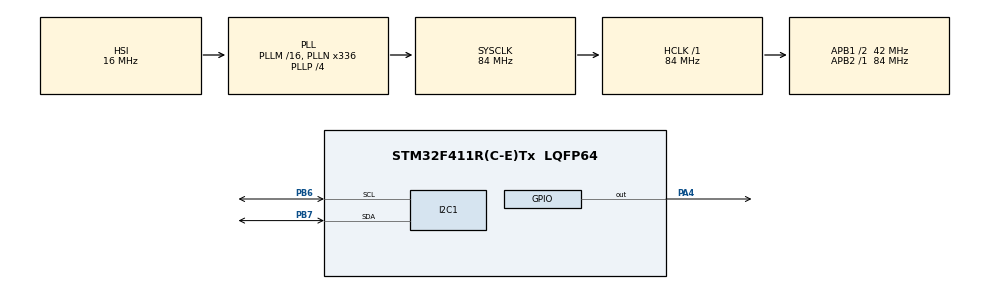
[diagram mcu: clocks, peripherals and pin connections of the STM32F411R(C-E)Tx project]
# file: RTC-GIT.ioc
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Mcu.Family=STM32F4
Mcu.Name=STM32F411R(C-E)Tx
Mcu.Package=LQFP64
NVIC.PriorityGroup=NVIC_PRIORITYGROUP_0
PA13.Mode=Trace_Asynchronous_SW
PA13.Signal=SYS_JTMS-SWDIO
PA14.Mode=Trace_Asynchronous_SW
PA14.Signal=SYS_JTCK-SWCLK
PA4.Signal=GPIO_Output
PB3.Mode=Trace_Asynchronous_SW
PB3.Signal=SYS_JTDO-SWO
PB6.Mode=I2C
PB6.Signal=I2C1_SCL
PB7.Mode=I2C
PB7.Signal=I2C1_SDA
ProjectManager.HeapSize=0x200
ProjectManager.StackSize=0x400
ProjectManager.TargetToolchain=STM32CubeIDE
RCC.48MHZClocksFreq_Value=84000000
RCC.AHBFreq_Value=84000000
RCC.APB1CLKDivider=RCC_HCLK_DIV2
RCC.APB1Freq_Value=42000000
RCC.APB1TimFreq_Value=84000000
RCC.APB2Freq_Value=84000000
RCC.APB2TimFreq_Value=84000000
RCC.CortexFreq_Value=84000000
RCC.FLatency-AdvancedSettings=FLASH_LATENCY_2
RCC.HCLKFreq_Value=84000000
RCC.HSE_VALUE=8000000
RCC.HSI_VALUE=16000000
RCC.PLLN=336
RCC.PLLP=RCC_PLLP_DIV4
RCC.SYSCLKFreq_VALUE=84000000
RCC.SYSCLKSource=RCC_SYSCLKSOURCE_PLLCLK
RCC.VCOOutputFreq_Value=336000000
board=NUCLEO-F411RE

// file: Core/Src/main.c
/* USER CODE BEGIN Header */
/**
  ******************************************************************************
  * @file           : main.c
  * @brief          : Main program body
  ******************************************************************************
  * @attention
  *
  * Copyright (c) 2026 STMicroelectronics.
  * All rights reserved.
  *
  * This software is licensed under terms that can be found in the LICENSE file
  * in the root directory of this software component.
  * If no LICENSE file comes with this software, it is provided AS-IS.
  *
  ******************************************************************************
  */
/* USER CODE END Header */
#include "main.h"

/* USER CODE BEGIN Includes */
#include <stdio.h>
/* USER CODE END Includes */

I2C_HandleTypeDef hi2c1;

void SystemClock_Config(void);
static void MX_GPIO_Init(void);
static void MX_I2C1_Init(void);
/* USER CODE BEGIN PFP */
int __io_putchar(int ch);
uint8_t time[7];

uint8_t data[7];

uint8_t DecToBCD(uint8_t val);
uint8_t BCDToDec(uint8_t val);

/* USER CODE END PFP */

int main(void)
{

  /* MCU Configuration--------------------------------------------------------*/

  /* Reset of all peripherals, Initializes the Flash interface and the Systick. */
  HAL_Init();

  /* Configure the system clock */
  SystemClock_Config();

  /* Initialize all configured peripherals */
  MX_GPIO_Init();
  MX_I2C1_Init();

  /* Infinite loop */
  while (1)
  {

	  HAL_I2C_Mem_Read(&hi2c1,
	                   0x68<<1,
	                   0x00,
	                   I2C_MEMADD_SIZE_8BIT,
	                   data,
	                   7,
	                   HAL_MAX_DELAY);

	  uint8_t sec  = BCDToDec(data[0]);
	  uint8_t min  = BCDToDec(data[1]);
	  uint8_t hour = BCDToDec(data[2]);
	  uint8_t date = BCDToDec(data[4]);
	  uint8_t mon  = BCDToDec(data[5]);
	  uint8_t year = BCDToDec(data[6]);

	  printf("%02d:%02d:%02d\r\n",
	          hour,
	          min,
	          sec);

	  printf("%02d/%02d/20%02d\r\n",
	          date,
	          mon,
	          year);

	  HAL_Delay(998);

  }
}

void SystemClock_Config(void)
{
  RCC_OscInitTypeDef RCC_OscInitStruct = {0};
  RCC_ClkInitTypeDef RCC_ClkInitStruct = {0};

  /** Configure the main internal regulator output voltage
  */
  __HAL_RCC_PWR_CLK_ENABLE();
  __HAL_PWR_VOLTAGESCALING_CONFIG(PWR_REGULATOR_VOLTAGE_SCALE1);

  /** Initializes the RCC Oscillators according to the specified parameters
  * in the RCC_OscInitTypeDef structure.
  */
  RCC_OscInitStruct.OscillatorType = RCC_OSCILLATORTYPE_HSI;
  RCC_OscInitStruct.HSIState = RCC_HSI_ON;
  RCC_OscInitStruct.HSICalibrationValue = RCC_HSICALIBRATION_DEFAULT;
  RCC_OscInitStruct.PLL.PLLState = RCC_PLL_ON;
  RCC_OscInitStruct.PLL.PLLSource = RCC_PLLSOURCE_HSI;
  RCC_OscInitStruct.PLL.PLLM = 16;
  RCC_OscInitStruct.PLL.PLLN = 336;
  RCC_OscInitStruct.PLL.PLLP = RCC_PLLP_DIV4;
  RCC_OscInitStruct.PLL.PLLQ = 4;
  if (HAL_RCC_OscConfig(&RCC_OscInitStruct) != HAL_OK)
  {
    Error_Handler();
  }

  /** Initializes the CPU, AHB and APB buses clocks
  */
  RCC_ClkInitStruct.ClockType = RCC_CLOCKTYPE_HCLK|RCC_CLOCKTYPE_SYSCLK
                              |RCC_CLOCKTYPE_PCLK1|RCC_CLOCKTYPE_PCLK2;
  RCC_ClkInitStruct.SYSCLKSource = RCC_SYSCLKSOURCE_PLLCLK;
  RCC_ClkInitStruct.AHBCLKDivider = RCC_SYSCLK_DIV1;
  RCC_ClkInitStruct.APB1CLKDivider = RCC_HCLK_DIV2;
  RCC_ClkInitStruct.APB2CLKDivider = RCC_HCLK_DIV1;

  if (HAL_RCC_ClockConfig(&RCC_ClkInitStruct, FLASH_LATENCY_2) != HAL_OK)
  {
    Error_Handler();
  }
}

static void MX_I2C1_Init(void)
{

  hi2c1.Instance = I2C1;
  hi2c1.Init.ClockSpeed = 100000;
  hi2c1.Init.DutyCycle = I2C_DUTYCYCLE_2;
  hi2c1.Init.OwnAddress1 = 0;
  hi2c1.Init.AddressingMode = I2C_ADDRESSINGMODE_7BIT;
  hi2c1.Init.DualAddressMode = I2C_DUALADDRESS_DISABLE;
  hi2c1.Init.OwnAddress2 = 0;
  hi2c1.Init.GeneralCallMode = I2C_GENERALCALL_DISABLE;
  hi2c1.Init.NoStretchMode = I2C_NOSTRETCH_DISABLE;
  if (HAL_I2C_Init(&hi2c1) != HAL_OK)
  {
    Error_Handler();
  }

}

static void MX_GPIO_Init(void)
{
  GPIO_InitTypeDef GPIO_InitStruct = {0};

  /* GPIO Ports Clock Enable */
  __HAL_RCC_GPIOA_CLK_ENABLE();
  __HAL_RCC_GPIOB_CLK_ENABLE();

  /*Configure GPIO pin Output Level */
  HAL_GPIO_WritePin(GPIOA, GPIO_PIN_4, GPIO_PIN_RESET);

  /*Configure GPIO pin : PA4 */
  GPIO_InitStruct.Pin = GPIO_PIN_4;
  GPIO_InitStruct.Mode = GPIO_MODE_OUTPUT_PP;
  GPIO_InitStruct.Pull = GPIO_NOPULL;
  GPIO_InitStruct.Speed = GPIO_SPEED_FREQ_LOW;
  HAL_GPIO_Init(GPIOA, &GPIO_InitStruct);

}

/* USER CODE BEGIN 4 */
int __io_putchar(int ch)
{
    ITM_SendChar(ch);
    return ch;
}

uint8_t DecToBCD(uint8_t val)
{
    return ((val / 10) << 4) | (val % 10);
}

uint8_t BCDToDec(uint8_t val)
{
    return ((val >> 4) * 10) + (val & 0x0F);
}
/* USER CODE END 4 */

void Error_Handler(void)
{
  __disable_irq();
  while (1)
  {
  }
}
